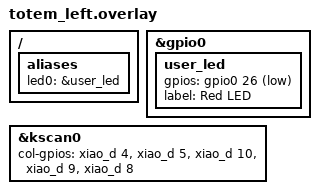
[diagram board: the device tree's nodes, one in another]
/*
 * Copyright (c) 2022 The ZMK Contributors aye
 *
 * SPDX-License-Identifier: MIT
 */

#include "totem.dtsi"

/ {
  aliases {
    led0 = &user_led;
  };
};

&gpio0 {
  user_led: user_led {
    gpios = <&gpio0 26 GPIO_ACTIVE_LOW>;
    label = "Red LED";
  };
};

&kscan0 {
    col-gpios
        = <&xiao_d 4 GPIO_ACTIVE_HIGH>
        , <&xiao_d 5 GPIO_ACTIVE_HIGH>
        , <&xiao_d 10 GPIO_ACTIVE_HIGH>
        , <&xiao_d 9 GPIO_ACTIVE_HIGH>
        , <&xiao_d 8 GPIO_ACTIVE_HIGH>
        ;
};
